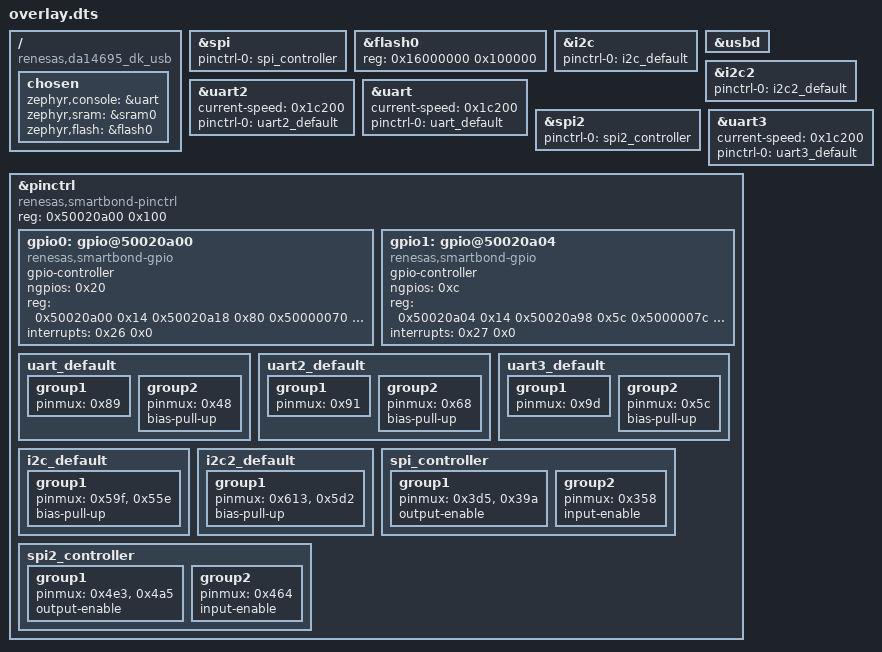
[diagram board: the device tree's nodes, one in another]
/ {
	compatible = "renesas,da14695_dk_usb";
	chosen {
		zephyr,console = &uart;
		zephyr,sram = &sram0;
		zephyr,flash = &flash0;
	};
};
&spi{
	status = "okay";
	pinctrl-0 = < &spi_controller >;
	pinctrl-names = "default";
};
&gpio1{
	status = "okay";
};
&flash0{
	reg = < 0x16000000 0x100000 >;
};
&i2c{
	status = "okay";
	pinctrl-0 = < &i2c_default >;
	pinctrl-names = "default";
};
&usbd{
	status = "okay";
};
&i2c2{
	status = "okay";
	pinctrl-0 = < &i2c2_default >;
	pinctrl-names = "default";
};
&gpio0{
	status = "okay";
};
&uart2{
	status = "okay";
	current-speed = < 0x1c200 >;
	pinctrl-0 = < &uart2_default >;
	pinctrl-names = "default";
};
&uart{
	status = "okay";
	current-speed = < 0x1c200 >;
	pinctrl-0 = < &uart_default >;
	pinctrl-names = "default";
};
&spi2{
	status = "okay";
	pinctrl-0 = < &spi2_controller >;
	pinctrl-names = "default";
};
&uart3{
	status = "okay";
	current-speed = < 0x1c200 >;
	pinctrl-0 = < &uart3_default >;
	pinctrl-names = "default";
};
&pinctrl{
	compatible = "renesas,smartbond-pinctrl";
	reg = < 0x50020a00 0x100 >;
	#address-cells = < 0x1 >;
	#size-cells = < 0x1 >;
	gpio0: gpio@50020a00 {
		compatible = "renesas,smartbond-gpio";
		gpio-controller;
		#gpio-cells = < 0x2 >;
		ngpios = < 0x20 >;
		reg = < 0x50020a00 0x14 0x50020a18 0x80 0x50000070 0xc 0x50000114 0x24 >;
		reg-names = "data", "mode", "latch", "wkup";
		interrupts = < 0x26 0x0 >;
		status = "okay";
	};
	gpio1: gpio@50020a04 {
		compatible = "renesas,smartbond-gpio";
		gpio-controller;
		#gpio-cells = < 0x2 >;
		ngpios = < 0xc >;
		reg = < 0x50020a04 0x14 0x50020a98 0x5c 0x5000007c 0xc 0x50000118 0x24 >;
		reg-names = "data", "mode", "latch", "wkup";
		interrupts = < 0x27 0x0 >;
		status = "okay";
	};
	uart_default: uart_default {
		group1 {
			pinmux = < 0x89 >;
		};
		group2 {
			pinmux = < 0x48 >;
			bias-pull-up;
		};
	};
	uart2_default: uart2_default {
		group1 {
			pinmux = < 0x91 >;
		};
		group2 {
			pinmux = < 0x68 >;
			bias-pull-up;
		};
	};
	uart3_default: uart3_default {
		group1 {
			pinmux = < 0x9d >;
		};
		group2 {
			pinmux = < 0x5c >;
			bias-pull-up;
		};
	};
	i2c_default: i2c_default {
		group1 {
			pinmux = < 0x59f >, < 0x55e >;
			bias-pull-up;
		};
	};
	i2c2_default: i2c2_default {
		group1 {
			pinmux = < 0x613 >, < 0x5d2 >;
			bias-pull-up;
		};
	};
	spi_controller: spi_controller {
		group1 {
			pinmux = < 0x3d5 >, < 0x39a >;
			output-enable;
		};
		group2 {
			pinmux = < 0x358 >;
			input-enable;
		};
	};
	spi2_controller: spi2_controller {
		group1 {
			pinmux = < 0x4e3 >, < 0x4a5 >;
			output-enable;
		};
		group2 {
			pinmux = < 0x464 >;
			input-enable;
		};
	};
};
